# TIMER0_CFG register map
Vendor: Texas Instruments
Peripheral module from a debugger description file (folder J7ES).
Registers are 32-bit, access per field, reset 0x0 unless marked. A register's access mark holds for its fields unless they carry their own. Offsets are as the file gives them; lines under a group give offsets from that group; [hi:lo] are bit positions; {n}, {i} and the like mark numbered series; 'fields as' and 'values as' point back to an identical list; <NAME> marks a mode.

## TIMER0_CFG
0x00 TIMER_TIDR ro reset 0x50003900 — This read-only register contains the revision number of the module. A write to this register has no effect. This register is used by software to track features, bugs, and compatibility.
  [31:0] REVISION — IP Revision
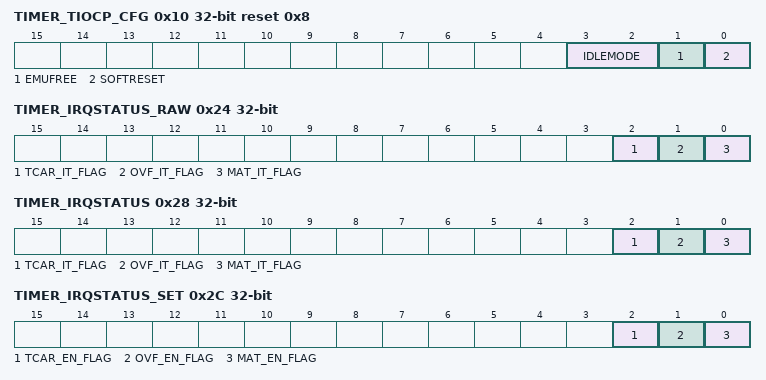
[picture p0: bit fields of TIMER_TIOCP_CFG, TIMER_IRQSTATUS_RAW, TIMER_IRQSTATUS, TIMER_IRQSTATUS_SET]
0x10 TIMER_TIOCP_CFG reset 0x8 — This register controls the various parameters of the CBASS0/MCU_CBASS0 interface. Some of the timers features described in this section may not be supported on this family of devices. For more information, see , Timers Not Supported Features.
  [3:2] IDLEMODE rw — Power management, req/ack control 0h = Force-idle mode: local target idle state follows (acknowledges) the system clock stop requests unconditionally, that is, regardless of the IP module internal requirements. Back-up mode, for debug only. 1h = No-idle mode: local target never enters idle state. Back-up mode, for debug only. 2h = Smart-idle mode: local target idle state eventually follows (acknowledges) the system clock stop requests, depending on the IP module internal requirements. IP module should not generate (IRQ-request-related) wake-up events. 3h = Smart-idle wake-up-capable mode: local target idle state eventually follows (acknowledges) the system clock stop requests, depending on the IP module internal requirements. IP module may generate (IRQ-request-related) wake-up events when in IDLE state. Mode is relevant only if the appropriate IP modules wake-up output(s) is (are) implemented.
  [1] EMUFREE rw — Emulation mode 0h = The timer is frozen in emulation mode (PINSUSPENDN signal active). 1h = The timer runs free, regardless of PINSUSPENDN value.
  [0] SOFTRESET rw — Software reset Read 0h = Reset done, no pending action
0x20 TIMER_IRQ_EOI — Software End-Of-Interrupt: Allows the generation of further pulses on the interrupt line, if a new interrupt event is pending, when using the pulsed output. Unused when using the level interrupt line (depending on module integration). The EOI register is used to re-trigger the pulse interrupt signal to ensure that any nested interrupt events are serviced. The software interrupt handler must write to the EOI register at the end of the current interrupt processing routine, so that new events can re-trigger the pulse interrupt signal again. For level interrupt signals the EOI register is not functional and must not be used.
  [0] LINE_NUMBER rw — Write the number of the interrupt line to apply a SW EOI to it. Note that there is only a single line (that is number 0).
0x24 TIMER_IRQSTATUS_RAW — Component interrupt-request status. Check the corresponding secondary status register. Raw status is set even if event is not enabled. Write 1 to set the (raw) status, mostly for debug.
  [2] TCAR_IT_FLAG rw — IRQ status for capture
  [1] OVF_IT_FLAG rw — IRQ status for overflow
  [0] MAT_IT_FLAG rw — IRQ status for match
0x28 TIMER_IRQSTATUS — Component interrupt-request status. Check the corresponding secondary status register. Enabled status is not set unless event is enabled. Write 1 to clear the status after interrupt has been serviced (raw status gets cleared, that is, even if not enabled).
  fields as TIMER_IRQSTATUS_RAW
0x2C TIMER_IRQSTATUS_SET — Component interrupt-request enable. Write 1 to set (enable interrupt). Readout equal to corresponding *_CLR register.
  [2] TCAR_EN_FLAG rw — IRQ enable for compare
  [1] OVF_EN_FLAG rw — IRQ enable for overflow
  [0] MAT_EN_FLAG rw — IRQ enable for match
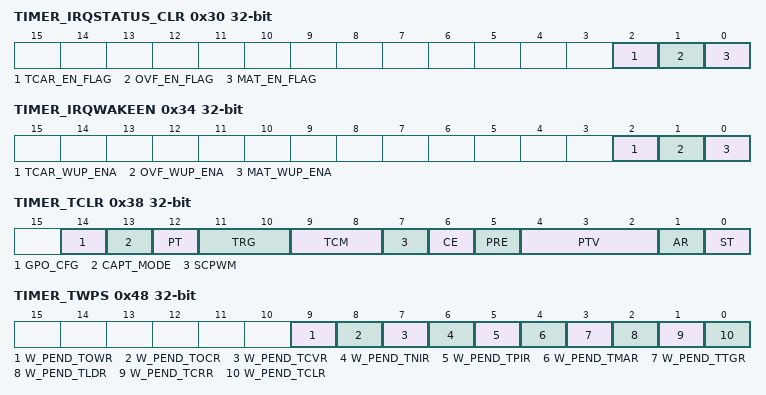
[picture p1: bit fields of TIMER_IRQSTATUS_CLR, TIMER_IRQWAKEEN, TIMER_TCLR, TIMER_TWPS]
0x30 TIMER_IRQSTATUS_CLR — Component interrupt-request enable. Write 1 to clear (disable interrupt). Readout equal to corresponding *_SET register.
  fields as TIMER_IRQSTATUS_SET
0x34 TIMER_IRQWAKEEN — Wake-up-enabled events taking place when module is idle should generate an asynchronous wake-up.
  [2] TCAR_WUP_ENA rw — Wake-up generation for compare 0h = Wake-up disabled 1h = Wake-up enabled.
  [1] OVF_WUP_ENA rw — Wake-up generation for overflow 0h = Wake-up disabled 1h = Wake-up enabled.
  [0] MAT_WUP_ENA rw — Wake-up generation for match 0h = Wake-up disabled 1h = Wake-up enabled.
0x38 TIMER_TCLR — This register controls optional features specific to the timer functionality.
  [14] GPO_CFG rw — General-purpose output - this bit is used to as an output enable for the TIMER IO pin. 0h = TIMER IO pin functions as PWM output. 1h = TIMER IO pin functions as TRIGGER input.
  [13] CAPT_MODE rw — Capture mode select bit (first/second) 0h = Single capture: Capture the first enabled capture event in 1h = Capture on second event: Capture the second enabled capture event in
  [12] PT rw — Pulse or toggle mode on POTIMERPWM output pin 0h = Pulse modulation 1h = Toggle modulation.
  [11:10] TRG rw — Trigger output mode on POTIMERPWM output pin 0h = No trigger 1h = Trigger on overflow. 2h = Trigger on overflow and match 3h = Reserved.
  [9:8] TCM rw — Transition capture mode on EVENT_CAPTURE input pin (When the TCM field passed from (00) to any other combination, the TCAR_IT_FLAG and the edge detection logic are cleared.) 0h = No capture 1h = Capture on rising edges of EVENT_CAPTURE pin 2h = Capture on falling edges of EVENT_CAPTURE pin 3h = Capture on both edges of EVENT_CAPTURE pin.
  [7] SCPWM rw — Pulse width modulation output pin default setting 0h = Clear the POTIMERPWM output pin and select positive pulse for pulse mode. 1h = Set the POTIMERPWM output pin and select negative pulse for pulse mode.
  [6] CE rw — Compare enable 0h = Compare mode is disable. 1h = Compare mode is enable.
  [5] PRE rw — Prescaler enable 0h = The timer clock input pin clocks the counter. 1h = The divided input pin clocks the counter.
  [4:2] PTV rw — Prescale clock timer value
  [1] AR rw — Autoreload mode 0h = One shot timer 1h = Autoreload timer
  [0] ST rw — Start/stop timer control 0h = Stop timer: Only the counter is frozen. If one-shot mode selected (AR = 0), this bit is automatically reset by internal logic when the counter is overflowed. 1h = Start timer.
0x3C TIMER_TCRR rw — This register holds the value of the internal counter.
  [31:0] TIMER_COUNTER — Value of timer counter
0x40 TIMER_TLDR rw — This register holds the timer load value.
  [31:0] LOAD_VALUE — Timer counter value loaded on overflow in autoreload mode or on
0x44 TIMER_TTGR rw reset 0xF — This register triggers a counter reload of timer by writing any value in it. The read value of this register is always FFFF FFFFh.
  [31:0] TTGR_VALUE — Writing to the
0x48 TIMER_TWPS ro — This register contains the write posting bits for all writable functional registers.
  [9] W_PEND_TOWR — Write pending for the Read 0h = No write pending Read 1h = Write pending.
  [8] W_PEND_TOCR — Write pending for the Read 0h = No write pending Read 1h = Write pending.
  [7] W_PEND_TCVR — Write pending for the Read 0h = No write pending Read 1h = Write pending.
  [6] W_PEND_TNIR — Write pending for the Read 0h = No negative increment register write pending Read 1h = Negative increment register write pending.
  [5] W_PEND_TPIR — Write pending for the Read 0h = No positive increment register write pending Read 1h = Positive increment register write pending.
  [4] W_PEND_TMAR — Write pending for theRead 0h = No write pending Read 1h = Write pending.
  [3] W_PEND_TTGR — Write pending for theRead 0h = No write pending Read 1h = Write pending.
  [2] W_PEND_TLDR — Write pending for theRead 0h = No write pending Read 1h = Write pending.
  [1] W_PEND_TCRR — Write pending for theRead 0h = No write pending Read 1h = Write pending.
  [0] W_PEND_TCLR — Write pending for theRead 0h = No write pending Read 1h = Write pending.
0x4C TIMER_TMAR rw — The register holds the match value to be compared with the counter's value.
  [31:0] COMPARE_VALUE — Value to be compared to the timer counter
0x50 TIMER_TCAR1 ro — This register holds the first captured value of the counter register.
  [31:0] CAPTURE_VALUE1 — First timer counter value captured on an external event trigger
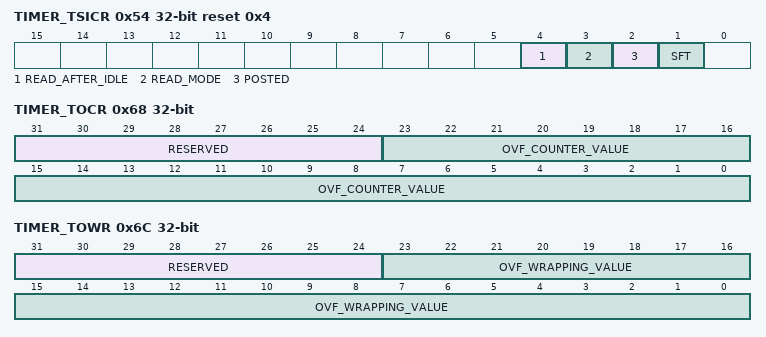
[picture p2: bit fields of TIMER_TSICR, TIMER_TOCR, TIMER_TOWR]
0x54 TIMER_TSICR reset 0x4 — Timer synchronous interface control register
  [4] READ_AFTER_IDLE wo — Select if the synchronization mechanism used for firstTIMER_TCRR read operation after idle state is active.Field values: 0h = The synchronization mechanism is enabled.1h = The synchronization mechanism is disabled.
  [3] READ_MODE wo — Select posted/non-posted mode for read operation: NOTE: When the module is configured in posted mode (POSTED = '1'), this bit is not used. 0h = When the module is configured in non-posted mode (POSTED = '0'), the read operation is executed as read posted. 1h = When the module is configured in non-posted mode (POSTED = '0'), the read operation is executed as read non-posted.
  [2] POSTED rw — Posted mode selection. 0h = Posted mode inactive: Delay the command accept output signal. 1h = Posted mode active.
  [1] SFT rw — This bit resets all the functional part of the module. All read accesses return 0. 0h = Software reset is disabled. 1h = Software reset is enabled.
0x58 TIMER_TCAR2 ro — This register holds the second captured value of the counter register.
  [31:0] CAPTURE_VALUE2 — Second timer counter value captured on an external event trigger
0x5C TIMER_TPIR rw — This register is used for 1-ms tick generation. The register holds the value of the positive increment. The value of this register is added to the value of to determine whether next value loaded in is the subperiod value or the overperiod value.
  [31:0] POSITIVE_INC_VALUE — Value of the positive increment
0x60 TIMER_TNIR rw — This register is used for 1-ms tick generation. The register holds the value of the negative increment. The value of this register is added to the value of the to determine whether next value loaded in is the subperiod value or the overperiod value.
  [31:0] NEGATIVE_INV_VALUE — Value of the negative increment
0x64 TIMER_TCVR rw — This register is used for 1-ms tick generation. The register determines whether next value loaded in is the subperiod value or the overperiod value.
  [31:0] COUNTER_VALUE — Value of CVR counter
0x68 TIMER_TOCR — This register is used to mask the tick interrupt for a selected number of ticks.
  [31:24] RESERVED ro — Reads return 0.
  [23:0] OVF_COUNTER_VALUE rw — Number of overflow events
0x6C TIMER_TOWR — This register holds the number of masked overflow interrupts.
  [31:24] RESERVED ro — Reads return 0.
  [23:0] OVF_WRAPPING_VALUE rw — Number of masked interrupts
